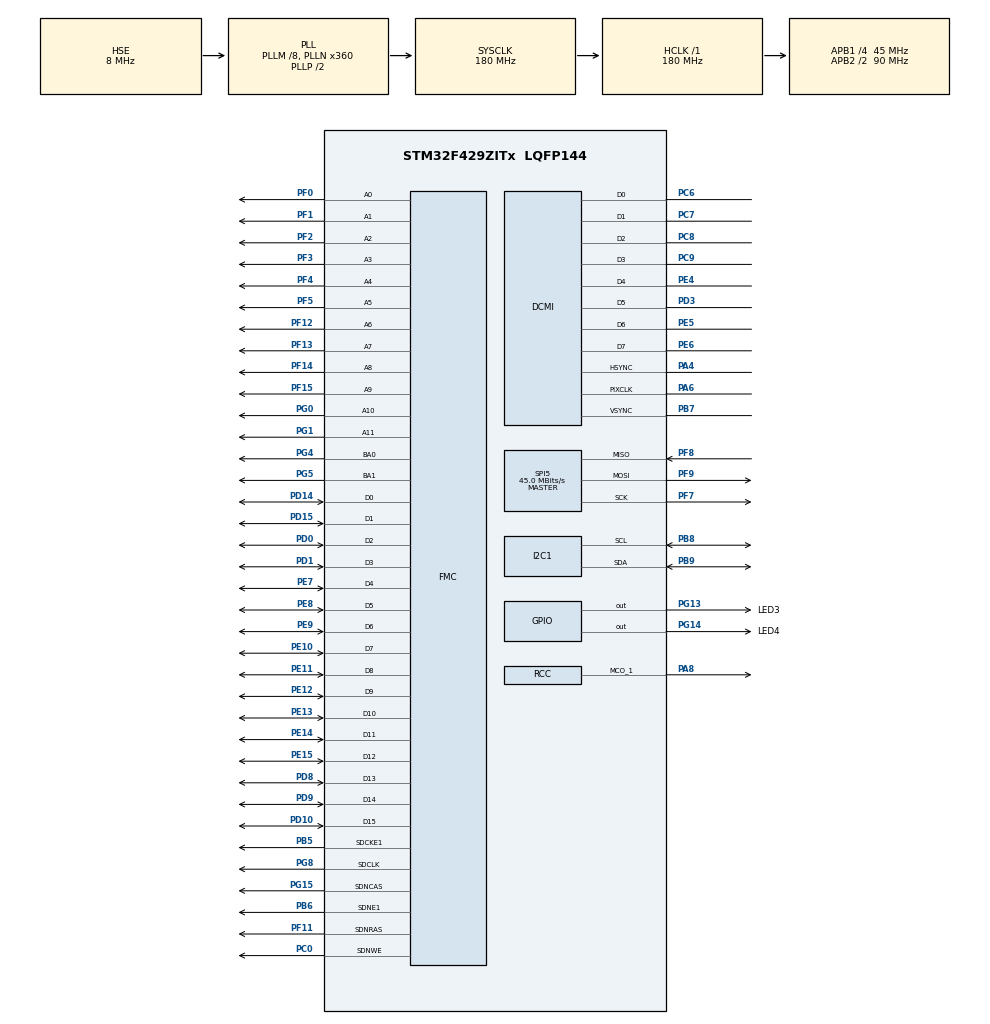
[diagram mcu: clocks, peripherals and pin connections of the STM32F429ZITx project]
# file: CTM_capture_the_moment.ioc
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DCMI.JPEGMode=DCMI_JPEG_DISABLE
Dma.DCMI.0.Direction=DMA_PERIPH_TO_MEMORY
Dma.DCMI.0.FIFOMode=DMA_FIFOMODE_DISABLE
Dma.DCMI.0.Instance=DMA2_Stream1
Dma.DCMI.0.MemDataAlignment=DMA_MDATAALIGN_WORD
Dma.DCMI.0.MemInc=DMA_MINC_ENABLE
Dma.DCMI.0.Mode=DMA_NORMAL
Dma.DCMI.0.PeriphDataAlignment=DMA_PDATAALIGN_WORD
Dma.DCMI.0.PeriphInc=DMA_PINC_DISABLE
Dma.DCMI.0.Priority=DMA_PRIORITY_HIGH
Dma.Request0=DCMI
FMC.CASLatency1=FMC_SDRAM_CAS_LATENCY_3
FMC.ExitSelfRefreshDelay1=7
FMC.LoadToActiveDelay1=2
FMC.RCDDelay1=2
FMC.RPDelay1=2
FMC.ReadBurst1=FMC_SDRAM_RBURST_DISABLE
FMC.ReadPipeDelay1=FMC_SDRAM_RPIPE_DELAY_1
FMC.RowCycleDelay1=7
FMC.SDClockPeriod1=FMC_SDRAM_CLOCK_PERIOD_3
FMC.SelfRefreshTime1=4
FMC.WriteRecoveryTime1=3
FREERTOS.BinarySemaphores01=sem_frame_captured,Dynamic,NULL,Available;sem_filter_done,Dynamic,NULL,Available
FREERTOS.Tasks01=CameraTask,24,128,StartCameraTask,Default,NULL,Dynamic,NULL,NULL;DisplayTask,8,128,StartDisplayTask,Default,NULL,Dynamic,NULL,NULL;FilterTask,8,128,StartFilterTask,Default,NULL,Dynamic,NULL,NULL
Mcu.Family=STM32F4
Mcu.Name=STM32F429ZITx
Mcu.Package=LQFP144
NVIC.DCMI_IRQn=true\:5\:0\:false\:false\:true\:true\:true\:true\:true
NVIC.DMA2_Stream1_IRQn=true\:5\:0\:false\:false\:true\:true\:false\:true\:true
NVIC.PriorityGroup=NVIC_PRIORITYGROUP_4
PA4.Mode=Slave_8_bits_External_Synchro
PA4.Signal=DCMI_HSYNC
PA6.Mode=Slave_8_bits_External_Synchro
PA6.Signal=DCMI_PIXCLK
PA8.GPIO_PuPd=GPIO_PULLUP
PA8.GPIO_Speed=GPIO_SPEED_FREQ_VERY_HIGH
PA8.Mode=Clock-out-1
PA8.Signal=RCC_MCO_1
PB5.Mode=SdramChipSelect2_1
PB5.Signal=FMC_SDCKE1
PB6.Mode=SdramChipSelect2_1
PB6.Signal=FMC_SDNE1
PB7.Mode=Slave_8_bits_External_Synchro
PB7.Signal=DCMI_VSYNC
PB8.GPIO_Pu=GPIO_PULLUP
PB8.Mode=I2C
PB8.Signal=I2C1_SCL
PB9.GPIO_Pu=GPIO_PULLUP
PB9.Mode=I2C
PB9.Signal=I2C1_SDA
PC0.Signal=FMC_SDNWE
PC6.Mode=Slave_8_bits_External_Synchro
PC6.Signal=DCMI_D0
PC7.Mode=Slave_8_bits_External_Synchro
PC7.Signal=DCMI_D1
PC8.Mode=Slave_8_bits_External_Synchro
PC8.Signal=DCMI_D2
PC9.Mode=Slave_8_bits_External_Synchro
PC9.Signal=DCMI_D3
PD0.Signal=FMC_D2_DA2
PD1.Signal=FMC_D3_DA3
PD10.Signal=FMC_D15_DA15
PD14.Signal=FMC_D0_DA0
PD15.Signal=FMC_D1_DA1
PD3.Mode=Slave_8_bits_External_Synchro
PD3.Signal=DCMI_D5
PD8.Signal=FMC_D13_DA13
PD9.Signal=FMC_D14_DA14
PE0.Signal=FMC_NBL0
PE1.Signal=FMC_NBL1
PE10.Signal=FMC_D7_DA7
PE11.Signal=FMC_D8_DA8
PE12.Signal=FMC_D9_DA9
PE13.Signal=FMC_D10_DA10
PE14.Signal=FMC_D11_DA11
PE15.Signal=FMC_D12_DA12
PE4.Mode=Slave_8_bits_External_Synchro
PE4.Signal=DCMI_D4
PE5.Mode=Slave_8_bits_External_Synchro
PE5.Signal=DCMI_D6
PE6.Mode=Slave_8_bits_External_Synchro
PE6.Signal=DCMI_D7
PE7.Signal=FMC_D4_DA4
PE8.Signal=FMC_D5_DA5
PE9.Signal=FMC_D6_DA6
PF0.Signal=FMC_A0
PF1.Signal=FMC_A1
PF11.Signal=FMC_SDNRAS
PF12.Signal=FMC_A6
PF13.Signal=FMC_A7
PF14.Signal=FMC_A8
PF15.Signal=FMC_A9
PF2.Signal=FMC_A2
PF3.Signal=FMC_A3
PF4.Signal=FMC_A4
PF5.Signal=FMC_A5
PF7.Mode=Full_Duplex_Master
PF7.Signal=SPI5_SCK
PF8.Mode=Full_Duplex_Master
PF8.Signal=SPI5_MISO
PF9.Mode=Full_Duplex_Master
PF9.Signal=SPI5_MOSI
PG0.Signal=FMC_A10
PG1.Signal=FMC_A11
PG13.GPIO_Label=LED3
PG13.Signal=GPIO_Output
PG14.GPIO_Label=LED4
PG14.Signal=GPIO_Output
PG15.Signal=FMC_SDNCAS
PG4.Signal=FMC_A14_BA0
PG5.Signal=FMC_A15_BA1
PG8.Signal=FMC_SDCLK
PH0/OSC_IN.Mode=HSE-External-Oscillator
PH0/OSC_IN.Signal=RCC_OSC_IN
PH1/OSC_OUT.Mode=HSE-External-Oscillator
PH1/OSC_OUT.Signal=RCC_OSC_OUT
ProjectManager.HeapSize=0x200
ProjectManager.StackSize=0x400
ProjectManager.TargetToolchain=STM32CubeIDE
RCC.48MHZClocksFreq_Value=51428571.428571425
RCC.AHBFreq_Value=180000000
RCC.APB1CLKDivider=RCC_HCLK_DIV4
RCC.APB1Freq_Value=45000000
RCC.APB1TimFreq_Value=90000000
RCC.APB2CLKDivider=RCC_HCLK_DIV2
RCC.APB2Freq_Value=90000000
RCC.APB2TimFreq_Value=180000000
RCC.CortexFreq_Value=180000000
RCC.HCLKFreq_Value=180000000
RCC.HSE_VALUE=8000000
RCC.HSI_VALUE=16000000
RCC.LSE_VALUE=32768
RCC.PLLM=8
RCC.PLLN=360
RCC.PLLQ=7
RCC.PLLSourceVirtual=RCC_PLLSOURCE_HSE
RCC.SYSCLKFreq_VALUE=180000000
RCC.SYSCLKSource=RCC_SYSCLKSOURCE_PLLCLK
RCC.VCOOutputFreq_Value=360000000
SH.FMC_A0.0=FMC_A0,12b-sda1
SH.FMC_A1.0=FMC_A1,12b-sda1
SH.FMC_A10.0=FMC_A10,12b-sda1
SH.FMC_A11.0=FMC_A11,12b-sda1
SH.FMC_A14_BA0.0=FMC_BA0,FourSdramBanks1
SH.FMC_A15_BA1.0=FMC_BA1,FourSdramBanks1
SH.FMC_A2.0=FMC_A2,12b-sda1
SH.FMC_A3.0=FMC_A3,12b-sda1
SH.FMC_A4.0=FMC_A4,12b-sda1
SH.FMC_A5.0=FMC_A5,12b-sda1
SH.FMC_A6.0=FMC_A6,12b-sda1
SH.FMC_A7.0=FMC_A7,12b-sda1
SH.FMC_A8.0=FMC_A8,12b-sda1
SH.FMC_A9.0=FMC_A9,12b-sda1
SH.FMC_D0_DA0.0=FMC_D0,sd-16b-d1
SH.FMC_D10_DA10.0=FMC_D10,sd-16b-d1
SH.FMC_D11_DA11.0=FMC_D11,sd-16b-d1
SH.FMC_D12_DA12.0=FMC_D12,sd-16b-d1
SH.FMC_D13_DA13.0=FMC_D13,sd-16b-d1
SH.FMC_D14_DA14.0=FMC_D14,sd-16b-d1
SH.FMC_D15_DA15.0=FMC_D15,sd-16b-d1
SH.FMC_D1_DA1.0=FMC_D1,sd-16b-d1
SH.FMC_D2_DA2.0=FMC_D2,sd-16b-d1
SH.FMC_D3_DA3.0=FMC_D3,sd-16b-d1
SH.FMC_D4_DA4.0=FMC_D4,sd-16b-d1
SH.FMC_D5_DA5.0=FMC_D5,sd-16b-d1
SH.FMC_D6_DA6.0=FMC_D6,sd-16b-d1
SH.FMC_D7_DA7.0=FMC_D7,sd-16b-d1
SH.FMC_D8_DA8.0=FMC_D8,sd-16b-d1
SH.FMC_D9_DA9.0=FMC_D9,sd-16b-d1
SH.FMC_NBL0.0=FMC_NBL0
SH.FMC_NBL1.0=FMC_NBL1
SH.FMC_SDCLK.0=FMC_SDCLK,12b-sda1
SH.FMC_SDNCAS.0=FMC_SDNCAS,12b-sda1
SH.FMC_SDNRAS.0=FMC_SDNRAS,12b-sda1
SH.FMC_SDNWE.0=FMC_SDNWE,12b-sda1
SPI5.CalculateBaudRate=45.0 MBits/s
SPI5.Direction=SPI_DIRECTION_2LINES
SPI5.Mode=SPI_MODE_MASTER
SPI5.VirtualType=VM_MASTER
VP_FREERTOS_VS_CMSIS_V2.Mode=CMSIS_V2
board=STM32F429I-DISC1

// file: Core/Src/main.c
/* USER CODE BEGIN Header */
/**
  ******************************************************************************
  * @file           : main.c
  * @brief          : Main program body
  ******************************************************************************
  * @attention
  *
  * Copyright (c) 2025 STMicroelectronics.
  * All rights reserved.
  *
  * This software is licensed under terms that can be found in the LICENSE file
  * in the root directory of this software component.
  * If no LICENSE file comes with this software, it is provided AS-IS.
  *
  ******************************************************************************
  */
/* USER CODE END Header */
#include "main.h"
#include "cmsis_os.h"

/* USER CODE BEGIN Includes */
#include "filter.h"
#include "lcd_drv.h"
#include "camera_drv.h"
/* USER CODE END Includes */

/* USER CODE BEGIN PD */
#define BUFFER_SIZE         ((uint32_t)0x0100)
#define WRITE_READ_ADDR     ((uint32_t)0x0800)
#define REFRESH_COUNT       ((uint32_t)0x056A)
static FilterType filterType = FILTER_NONE;

// Filtre değiştirme fonksiyonu
void cycleFilterType(void) {
    switch(filterType) {
        case FILTER_NONE:
            filterType = FILTER_GRAYSCALE;
            break;
        case FILTER_GRAYSCALE:
            filterType = FILTER_LAPLACIAN;
            break;
        case FILTER_LAPLACIAN:
            filterType = FILTER_GAUSSIAN;
            break;
        case FILTER_GAUSSIAN:
            filterType = FILTER_ROI;
            break;
        case FILTER_ROI:
        	filterType = FILTER_ROI_CENTER_ALARM;
        	break;
        case FILTER_ROI_CENTER_ALARM:
        	filterType = FILTER_NONE;
        	break;
        default:
            filterType = FILTER_NONE;
            break;
    }
}

// Test Defines
// Test görüntüsü boyutları
#define TEST_WIDTH 32
#define TEST_HEIGHT 32

// Test sonuçları için renkli çıktı
#define ANSI_COLOR_GREEN   "\x1b[32m"
#define ANSI_COLOR_RED     "\x1b[31m"
#define ANSI_COLOR_RESET   "\x1b[0m"

static void Fill_Buffer(uint32_t *pBuffer, uint32_t uwBufferLenght, uint32_t uwOffset);
/* USER CODE END PD */

DCMI_HandleTypeDef hdcmi;
DMA_HandleTypeDef hdma_dcmi;

I2C_HandleTypeDef hi2c1;

SPI_HandleTypeDef hspi5;

SDRAM_HandleTypeDef hsdram1;

/* Definitions for CameraTask */
osThreadId_t CameraTaskHandle;
const osThreadAttr_t CameraTask_attributes = {
  .name = "CameraTask",
  .stack_size = 128 * 4,
  .priority = (osPriority_t) osPriorityNormal,
};
/* Definitions for DisplayTask */
osThreadId_t DisplayTaskHandle;
const osThreadAttr_t DisplayTask_attributes = {
  .name = "DisplayTask",
  .stack_size = 128 * 4,
  .priority = (osPriority_t) osPriorityLow,
};
/* Definitions for FilterTask */
osThreadId_t FilterTaskHandle;
const osThreadAttr_t FilterTask_attributes = {
  .name = "FilterTask",
  .stack_size = 128 * 4,
  .priority = (osPriority_t) osPriorityLow,
};
/* Definitions for sem_frame_captured */
osSemaphoreId_t sem_frame_capturedHandle;
const osSemaphoreAttr_t sem_frame_captured_attributes = {
  .name = "sem_frame_captured"
};
/* Definitions for sem_filter_done */
osSemaphoreId_t sem_filter_doneHandle;
const osSemaphoreAttr_t sem_filter_done_attributes = {
  .name = "sem_filter_done"
};
/* USER CODE BEGIN PV */
FMC_SDRAM_CommandTypeDef command;
/* SDRAM Test  */
/* Read/Write Buffers */
uint32_t aTxBuffer[BUFFER_SIZE];
uint32_t aRxBuffer[BUFFER_SIZE];

/* Status variables */
__IO uint32_t uwWriteReadStatus = 0;

/* Counter index */
uint32_t uwIndex = 0;

/*Camera Variables */
uint16_t line_buffer[3][IMG_COLUMNS];             // 3 satırlık geçici buffer
uint16_t raw_image[IMG_ROWS * IMG_COLUMNS]; // Çıkış (her zaman RGB565)
__attribute__((section(".sdram"))) uint16_t filtered_image[IMG_ROWS * IMG_COLUMNS]; // Çıkış (her zaman RGB565)

// filter test
uint8_t grayscale_success, laplacian_success, roiopt_success, roialarm_success;

/* USER CODE END PV */

void SystemClock_Config(void);
static void MX_GPIO_Init(void);
static void MX_DMA_Init(void);
static void MX_SPI5_Init(void);
static void MX_DCMI_Init(void);
static void MX_I2C1_Init(void);
static void MX_FMC_Init(void);
void StartCameraTask(void *argument);
void StartDisplayTask(void *argument);
void StartFilterTask(void *argument);

/* USER CODE BEGIN PFP */
static void SDRAM_Initialization_Sequence(SDRAM_HandleTypeDef *hsdram, FMC_SDRAM_CommandTypeDef *Command);
/* USER CODE END PFP */

int main(void)
{

  /* MCU Configuration--------------------------------------------------------*/

  /* Reset of all peripherals, Initializes the Flash interface and the Systick. */
  HAL_Init();

  /* USER CODE BEGIN Init */
  te_CAMERA_ERROR_CODES cam_error;
  /* USER CODE END Init */

  /* Configure the system clock */
  SystemClock_Config();

  /* Initialize all configured peripherals */
  MX_GPIO_Init();
  MX_DMA_Init();
  MX_SPI5_Init();
  MX_DCMI_Init();
  MX_I2C1_Init();
  MX_FMC_Init();
  /* USER CODE BEGIN 2 */
  grayscale_success=0;
  laplacian_success=0;
  roiopt_success=0;
  roialarm_success=0;

  HAL_GPIO_WritePin(LED4_GPIO_Port, LED4_Pin, GPIO_PIN_SET);
  HAL_GPIO_WritePin(LED3_GPIO_Port, LED3_Pin, GPIO_PIN_SET);
  LCD_Open(NULL);
  cam_error = Camera_Open();

  if (cam_error != E_CAMERA_ERR_NONE) while(1);

  if (HAL_DCMI_Start_DMA(&hdcmi, DCMI_MODE_CONTINUOUS, (uint32_t)raw_image, IMG_ROWS*IMG_COLUMNS/2) != HAL_OK) {
    Error_Handler();
  }
  HAL_GPIO_WritePin(LED4_GPIO_Port, LED4_Pin, GPIO_PIN_RESET);
  HAL_GPIO_WritePin(LED3_GPIO_Port, LED3_Pin, GPIO_PIN_RESET);

  __HAL_DCMI_ENABLE_IT(&hdcmi, DCMI_IT_FRAME);

  /* Program the SDRAM external device */
    SDRAM_Initialization_Sequence(&hsdram1, &command);

    /* Fill the buffer to write */
      Fill_Buffer(aTxBuffer, BUFFER_SIZE, 0xA244250F);

      /* Write data to the SDRAM memory */
      for (uwIndex = 0; uwIndex < BUFFER_SIZE; uwIndex++)
      {
        *(__IO uint32_t*) (SDRAM_BANK_ADDR + WRITE_READ_ADDR + 4*uwIndex) = aTxBuffer[uwIndex];
      }

      /* Read back data from the SDRAM memory */
      for (uwIndex = 0; uwIndex < BUFFER_SIZE; uwIndex++)
      {
        aRxBuffer[uwIndex] = *(__IO uint32_t*) (SDRAM_BANK_ADDR + WRITE_READ_ADDR + 4*uwIndex);
       }

      /*##-3- Checking data integrity ############################################*/

        for (uwIndex = 0; (uwIndex < BUFFER_SIZE) && (uwWriteReadStatus == 0); uwIndex++)
        {
          if (aRxBuffer[uwIndex] != aTxBuffer[uwIndex])
          {
            uwWriteReadStatus++;
          }
        }

        if (uwWriteReadStatus)
        {
          /* KO */
          /* Turn on LED4 */
        	HAL_GPIO_WritePin(LED4_GPIO_Port, LED4_Pin, GPIO_PIN_SET);
        }
        else
        {
          /* OK */
          /* Turn on LED3 */
        	HAL_GPIO_WritePin(LED3_GPIO_Port, LED3_Pin, GPIO_PIN_SET);
        }

     // Filter Code Test
        //runFilterTests();
  /* USER CODE END 2 */

  /* Init scheduler */
  osKernelInitialize();

  /* Create the semaphores(s) */
  /* creation of sem_frame_captured */
  sem_frame_capturedHandle = osSemaphoreNew(1, 1, &sem_frame_captured_attributes);

  /* creation of sem_filter_done */
  sem_filter_doneHandle = osSemaphoreNew(1, 1, &sem_filter_done_attributes);

  /* Create the thread(s) */
  /* creation of CameraTask */
  CameraTaskHandle = osThreadNew(StartCameraTask, NULL, &CameraTask_attributes);

  /* creation of DisplayTask */
  DisplayTaskHandle = osThreadNew(StartDisplayTask, NULL, &DisplayTask_attributes);

  /* creation of FilterTask */
  FilterTaskHandle = osThreadNew(StartFilterTask, NULL, &FilterTask_attributes);

  /* Start scheduler */
  osKernelStart();

  /* We should never get here as control is now taken by the scheduler */

  /* Infinite loop */
  while (1)
  {

    /* USER CODE BEGIN 3 */
    // LCD_Display_Image((uint16_t *) processed_image);
  }
  /* USER CODE END 3 */
}

void SystemClock_Config(void)
{
  RCC_OscInitTypeDef RCC_OscInitStruct = {0};
  RCC_ClkInitTypeDef RCC_ClkInitStruct = {0};

  /** Configure the main internal regulator output voltage
  */
  __HAL_RCC_PWR_CLK_ENABLE();
  __HAL_PWR_VOLTAGESCALING_CONFIG(PWR_REGULATOR_VOLTAGE_SCALE1);

  /** Initializes the RCC Oscillators according to the specified parameters
  * in the RCC_OscInitTypeDef structure.
  */
  RCC_OscInitStruct.OscillatorType = RCC_OSCILLATORTYPE_HSI|RCC_OSCILLATORTYPE_HSE;
  RCC_OscInitStruct.HSEState = RCC_HSE_ON;
  RCC_OscInitStruct.HSIState = RCC_HSI_ON;
  RCC_OscInitStruct.HSICalibrationValue = RCC_HSICALIBRATION_DEFAULT;
  RCC_OscInitStruct.PLL.PLLState = RCC_PLL_ON;
  RCC_OscInitStruct.PLL.PLLSource = RCC_PLLSOURCE_HSE;
  RCC_OscInitStruct.PLL.PLLM = 8;
  RCC_OscInitStruct.PLL.PLLN = 360;
  RCC_OscInitStruct.PLL.PLLP = RCC_PLLP_DIV2;
  RCC_OscInitStruct.PLL.PLLQ = 7;
  if (HAL_RCC_OscConfig(&RCC_OscInitStruct) != HAL_OK)
  {
    Error_Handler();
  }

  /** Activate the Over-Drive mode
  */
  if (HAL_PWREx_EnableOverDrive() != HAL_OK)
  {
    Error_Handler();
  }

  /** Initializes the CPU, AHB and APB buses clocks
  */
  RCC_ClkInitStruct.ClockType = RCC_CLOCKTYPE_HCLK|RCC_CLOCKTYPE_SYSCLK
                              |RCC_CLOCKTYPE_PCLK1|RCC_CLOCKTYPE_PCLK2;
  RCC_ClkInitStruct.SYSCLKSource = RCC_SYSCLKSOURCE_PLLCLK;
  RCC_ClkInitStruct.AHBCLKDivider = RCC_SYSCLK_DIV1;
  RCC_ClkInitStruct.APB1CLKDivider = RCC_HCLK_DIV4;
  RCC_ClkInitStruct.APB2CLKDivider = RCC_HCLK_DIV2;

  if (HAL_RCC_ClockConfig(&RCC_ClkInitStruct, FLASH_LATENCY_5) != HAL_OK)
  {
    Error_Handler();
  }
  HAL_RCC_MCOConfig(RCC_MCO1, RCC_MCO1SOURCE_HSI, RCC_MCODIV_1);
}

static void MX_DCMI_Init(void)
{

  hdcmi.Instance = DCMI;
  hdcmi.Init.SynchroMode = DCMI_SYNCHRO_HARDWARE;
  hdcmi.Init.PCKPolarity = DCMI_PCKPOLARITY_FALLING;
  hdcmi.Init.VSPolarity = DCMI_VSPOLARITY_LOW;
  hdcmi.Init.HSPolarity = DCMI_HSPOLARITY_LOW;
  hdcmi.Init.CaptureRate = DCMI_CR_ALL_FRAME;
  hdcmi.Init.ExtendedDataMode = DCMI_EXTEND_DATA_8B;
  hdcmi.Init.JPEGMode = DCMI_JPEG_DISABLE;
  if (HAL_DCMI_Init(&hdcmi) != HAL_OK)
  {
    Error_Handler();
  }

}

static void MX_I2C1_Init(void)
{

  hi2c1.Instance = I2C1;
  hi2c1.Init.ClockSpeed = 100000;
  hi2c1.Init.DutyCycle = I2C_DUTYCYCLE_2;
  hi2c1.Init.OwnAddress1 = 0;
  hi2c1.Init.AddressingMode = I2C_ADDRESSINGMODE_7BIT;
  hi2c1.Init.DualAddressMode = I2C_DUALADDRESS_DISABLE;
  hi2c1.Init.OwnAddress2 = 0;
  hi2c1.Init.GeneralCallMode = I2C_GENERALCALL_DISABLE;
  hi2c1.Init.NoStretchMode = I2C_NOSTRETCH_DISABLE;
  if (HAL_I2C_Init(&hi2c1) != HAL_OK)
  {
    Error_Handler();
  }

  /** Configure Analogue filter
  */
  if (HAL_I2CEx_ConfigAnalogFilter(&hi2c1, I2C_ANALOGFILTER_ENABLE) != HAL_OK)
  {
    Error_Handler();
  }

  /** Configure Digital filter
  */
  if (HAL_I2CEx_ConfigDigitalFilter(&hi2c1, 0) != HAL_OK)
  {
    Error_Handler();
  }

}

static void MX_SPI5_Init(void)
{

  /* SPI5 parameter configuration*/
  hspi5.Instance = SPI5;
  hspi5.Init.Mode = SPI_MODE_MASTER;
  hspi5.Init.Direction = SPI_DIRECTION_2LINES;
  hspi5.Init.DataSize = SPI_DATASIZE_8BIT;
  hspi5.Init.CLKPolarity = SPI_POLARITY_LOW;
  hspi5.Init.CLKPhase = SPI_PHASE_1EDGE;
  hspi5.Init.NSS = SPI_NSS_SOFT;
  hspi5.Init.BaudRatePrescaler = SPI_BAUDRATEPRESCALER_2;
  hspi5.Init.FirstBit = SPI_FIRSTBIT_MSB;
  hspi5.Init.TIMode = SPI_TIMODE_DISABLE;
  hspi5.Init.CRCCalculation = SPI_CRCCALCULATION_DISABLE;
  hspi5.Init.CRCPolynomial = 10;
  if (HAL_SPI_Init(&hspi5) != HAL_OK)
  {
    Error_Handler();
  }

}

static void MX_DMA_Init(void)
{

  /* DMA controller clock enable */
  __HAL_RCC_DMA2_CLK_ENABLE();

  /* DMA interrupt init */
  /* DMA2_Stream1_IRQn interrupt configuration */
  HAL_NVIC_SetPriority(DMA2_Stream1_IRQn, 5, 0);
  HAL_NVIC_EnableIRQ(DMA2_Stream1_IRQn);

}

/* FMC initialization function */
static void MX_FMC_Init(void)
{

  FMC_SDRAM_TimingTypeDef SdramTiming = {0};

  /** Perform the SDRAM1 memory initialization sequence
  */
  hsdram1.Instance = FMC_SDRAM_DEVICE;
  /* hsdram1.Init */
  hsdram1.Init.SDBank = FMC_SDRAM_BANK2;
  hsdram1.Init.ColumnBitsNumber = FMC_SDRAM_COLUMN_BITS_NUM_8;
  hsdram1.Init.RowBitsNumber = FMC_SDRAM_ROW_BITS_NUM_12;
  hsdram1.Init.MemoryDataWidth = FMC_SDRAM_MEM_BUS_WIDTH_16;
  hsdram1.Init.InternalBankNumber = FMC_SDRAM_INTERN_BANKS_NUM_4;
  hsdram1.Init.CASLatency = FMC_SDRAM_CAS_LATENCY_3;
  hsdram1.Init.WriteProtection = FMC_SDRAM_WRITE_PROTECTION_DISABLE;
  hsdram1.Init.SDClockPeriod = FMC_SDRAM_CLOCK_PERIOD_3;
  hsdram1.Init.ReadBurst = FMC_SDRAM_RBURST_DISABLE;
  hsdram1.Init.ReadPipeDelay = FMC_SDRAM_RPIPE_DELAY_1;
  /* SdramTiming */
  SdramTiming.LoadToActiveDelay = 2;
  SdramTiming.ExitSelfRefreshDelay = 7;
  SdramTiming.SelfRefreshTime = 4;
  SdramTiming.RowCycleDelay = 7;
  SdramTiming.WriteRecoveryTime = 3;
  SdramTiming.RPDelay = 2;
  SdramTiming.RCDDelay = 2;

  if (HAL_SDRAM_Init(&hsdram1, &SdramTiming) != HAL_OK)
  {
    Error_Handler( );
  }

  /* USER CODE BEGIN FMC_Init 2 */
  static GPIO_TypeDef * const GPIOInitTable[] = {
    GPIOF, GPIOF, GPIOF, GPIOF, GPIOF, GPIOF, GPIOF, GPIOF, GPIOF, GPIOF, GPIOG, GPIOG,
    GPIOD, GPIOD, GPIOD, GPIOD, GPIOE, GPIOE, GPIOE, GPIOE, GPIOE, GPIOE, GPIOE, GPIOE, GPIOE, GPIOD,   GPIOD, GPIOD,
    GPIOB, GPIOB, GPIOC, GPIOE, GPIOE, GPIOF, GPIOG, GPIOG, GPIOG, GPIOG,
    0};

  static uint8_t const PINInitTable[] = {
    0, 1, 2, 3, 4, 5, 12, 13, 14, 15, 0, 1,
    14, 15, 0, 1, 7, 8, 9, 10, 11, 12, 13, 14, 15, 8,
    9, 10,
    5, 6, 0, 0, 1, 11, 4, 5, 8, 15,
    0};

  /* USER CODE END FMC_Init 2 */
}

static void MX_GPIO_Init(void)
{
  GPIO_InitTypeDef GPIO_InitStruct = {0};

  /* GPIO Ports Clock Enable */
  __HAL_RCC_GPIOE_CLK_ENABLE();
  __HAL_RCC_GPIOF_CLK_ENABLE();
  __HAL_RCC_GPIOH_CLK_ENABLE();
  __HAL_RCC_GPIOC_CLK_ENABLE();
  __HAL_RCC_GPIOA_CLK_ENABLE();
  __HAL_RCC_GPIOG_CLK_ENABLE();
  __HAL_RCC_GPIOD_CLK_ENABLE();
  __HAL_RCC_GPIOB_CLK_ENABLE();

  /*Configure GPIO pin Output Level */
  HAL_GPIO_WritePin(GPIOG, LED3_Pin|LED4_Pin, GPIO_PIN_RESET);

  // Filtre değiştirme butonu için GPIO ayarı
  GPIO_InitStruct.Pin = GPIO_PIN_0;
  GPIO_InitStruct.Mode = GPIO_MODE_IT_RISING;
  GPIO_InitStruct.Pull = GPIO_PULLDOWN;
  HAL_GPIO_Init(GPIOA, &GPIO_InitStruct);

  // Buton interrupt'ını aktifleştir
  HAL_NVIC_SetPriority(EXTI0_IRQn, 5, 0);
  HAL_NVIC_EnableIRQ(EXTI0_IRQn);

  /*Configure GPIO pin : PA8 */
  GPIO_InitStruct.Pin = GPIO_PIN_8;
  GPIO_InitStruct.Mode = GPIO_MODE_AF_PP;
  GPIO_InitStruct.Pull = GPIO_PULLUP;
  GPIO_InitStruct.Speed = GPIO_SPEED_FREQ_VERY_HIGH;
  GPIO_InitStruct.Alternate = GPIO_AF0_MCO;
  HAL_GPIO_Init(GPIOA, &GPIO_InitStruct);

  /*Configure GPIO pins : LED3_Pin LED4_Pin */
  GPIO_InitStruct.Pin = LED3_Pin|LED4_Pin;
  GPIO_InitStruct.Mode = GPIO_MODE_OUTPUT_PP;
  GPIO_InitStruct.Pull = GPIO_NOPULL;
  GPIO_InitStruct.Speed = GPIO_SPEED_FREQ_LOW;
  HAL_GPIO_Init(GPIOG, &GPIO_InitStruct);

  /* USER CODE BEGIN MX_GPIO_Init_2 */
  // FMC_D0 - PD14
  __HAL_RCC_GPIOD_CLK_ENABLE();
  GPIO_InitStruct.Pin = GPIO_PIN_14;
  GPIO_InitStruct.Mode = GPIO_MODE_AF_PP;
  GPIO_InitStruct.Pull = GPIO_NOPULL;
  GPIO_InitStruct.Speed = GPIO_SPEED_FREQ_VERY_HIGH;
  GPIO_InitStruct.Alternate = GPIO_AF12_FMC;
  HAL_GPIO_Init(GPIOD, &GPIO_InitStruct);

  // FMC_D1 - PD15
  __HAL_RCC_GPIOD_CLK_ENABLE();
  GPIO_InitStruct.Pin = GPIO_PIN_15;
  GPIO_InitStruct.Mode = GPIO_MODE_AF_PP;
  GPIO_InitStruct.Pull = GPIO_NOPULL;
  GPIO_InitStruct.Speed = GPIO_SPEED_FREQ_VERY_HIGH;
  GPIO_InitStruct.Alternate = GPIO_AF12_FMC;
  HAL_GPIO_Init(GPIOD, &GPIO_InitStruct);

  // FMC_D2 - PD0
  __HAL_RCC_GPIOD_CLK_ENABLE();
  GPIO_InitStruct.Pin = GPIO_PIN_0;
  GPIO_InitStruct.Mode = GPIO_MODE_AF_PP;
  GPIO_InitStruct.Pull = GPIO_NOPULL;
  GPIO_InitStruct.Speed = GPIO_SPEED_FREQ_VERY_HIGH;
  GPIO_InitStruct.Alternate = GPIO_AF12_FMC;
  HAL_GPIO_Init(GPIOD, &GPIO_InitStruct);

  // FMC_D3 - PD1
  __HAL_RCC_GPIOD_CLK_ENABLE();
  GPIO_InitStruct.Pin = GPIO_PIN_1;
  GPIO_InitStruct.Mode = GPIO_MODE_AF_PP;
  GPIO_InitStruct.Pull = GPIO_NOPULL;
  GPIO_InitStruct.Speed = GPIO_SPEED_FREQ_VERY_HIGH;
  GPIO_InitStruct.Alternate = GPIO_AF12_FMC;
  HAL_GPIO_Init(GPIOD, &GPIO_InitStruct);

  // FMC_D4 - PE7
  __HAL_RCC_GPIOE_CLK_ENABLE();
  GPIO_InitStruct.Pin = GPIO_PIN_7;
  GPIO_InitStruct.Mode = GPIO_MODE_AF_PP;
  GPIO_InitStruct.Pull = GPIO_NOPULL;
  GPIO_InitStruct.Speed = GPIO_SPEED_FREQ_VERY_HIGH;
  GPIO_InitStruct.Alternate = GPIO_AF12_FMC;
  HAL_GPIO_Init(GPIOE, &GPIO_InitStruct);

  // FMC_D5 - PE8
  __HAL_RCC_GPIOE_CLK_ENABLE();
  GPIO_InitStruct.Pin = GPIO_PIN_8;
  GPIO_InitStruct.Mode = GPIO_MODE_AF_PP;
  GPIO_InitStruct.Pull = GPIO_NOPULL;
  GPIO_InitStruct.Speed = GPIO_SPEED_FREQ_VERY_HIGH;
  GPIO_InitStruct.Alternate = GPIO_AF12_FMC;
  HAL_GPIO_Init(GPIOE, &GPIO_InitStruct);

  // FMC_D6 - PE9
  __HAL_RCC_GPIOE_CLK_ENABLE();
  GPIO_InitStruct.Pin = GPIO_PIN_9;
  GPIO_InitStruct.Mode = GPIO_MODE_AF_PP;
  GPIO_InitStruct.Pull = GPIO_NOPULL;
  GPIO_InitStruct.Speed = GPIO_SPEED_FREQ_VERY_HIGH;
  GPIO_InitStruct.Alternate = GPIO_AF12_FMC;
  HAL_GPIO_Init(GPIOE, &GPIO_InitStruct);

  // FMC_D7 - PE10
  __HAL_RCC_GPIOE_CLK_ENABLE();
  GPIO_InitStruct.Pin = GPIO_PIN_10;
  GPIO_InitStruct.Mode = GPIO_MODE_AF_PP;
  GPIO_InitStruct.Pull = GPIO_NOPULL;
  GPIO_InitStruct.Speed = GPIO_SPEED_FREQ_VERY_HIGH;
  GPIO_InitStruct.Alternate = GPIO_AF12_FMC;
  HAL_GPIO_Init(GPIOE, &GPIO_InitStruct);

  // FMC_D8 - PE11
  __HAL_RCC_GPIOE_CLK_ENABLE();
  GPIO_InitStruct.Pin = GPIO_PIN_11;
  GPIO_InitStruct.Mode = GPIO_MODE_AF_PP;
  GPIO_InitStruct.Pull = GPIO_NOPULL;
  GPIO_InitStruct.Speed = GPIO_SPEED_FREQ_VERY_HIGH;
  GPIO_InitStruct.Alternate = GPIO_AF12_FMC;
  HAL_GPIO_Init(GPIOE, &GPIO_InitStruct);

  // FMC_D9 - PE12
  __HAL_RCC_GPIOE_CLK_ENABLE();
  GPIO_InitStruct.Pin = GPIO_PIN_12;
  GPIO_InitStruct.Mode = GPIO_MODE_AF_PP;
  GPIO_InitStruct.Pull = GPIO_NOPULL;
  GPIO_InitStruct.Speed = GPIO_SPEED_FREQ_VERY_HIGH;
  GPIO_InitStruct.Alternate = GPIO_AF12_FMC;
  HAL_GPIO_Init(GPIOE, &GPIO_InitStruct);

  // FMC_D10 - PE13
  __HAL_RCC_GPIOE_CLK_ENABLE();
  GPIO_InitStruct.Pin = GPIO_PIN_13;
  GPIO_InitStruct.Mode = GPIO_MODE_AF_PP;
  GPIO_InitStruct.Pull = GPIO_NOPULL;
  GPIO_InitStruct.Speed = GPIO_SPEED_FREQ_VERY_HIGH;
  GPIO_InitStruct.Alternate = GPIO_AF12_FMC;
  HAL_GPIO_Init(GPIOE, &GPIO_InitStruct);

  // FMC_D11 - PE14
  __HAL_RCC_GPIOE_CLK_ENABLE();
  GPIO_InitStruct.Pin = GPIO_PIN_14;
  GPIO_InitStruct.Mode = GPIO_MODE_AF_PP;
  GPIO_InitStruct.Pull = GPIO_NOPULL;
  GPIO_InitStruct.Speed = GPIO_SPEED_FREQ_VERY_HIGH;
  GPIO_InitStruct.Alternate = GPIO_AF12_FMC;
  HAL_GPIO_Init(GPIOE, &GPIO_InitStruct);

  // FMC_D12 - PE15
  __HAL_RCC_GPIOE_CLK_ENABLE();
  GPIO_InitStruct.Pin = GPIO_PIN_15;
  GPIO_InitStruct.Mode = GPIO_MODE_AF_PP;
  GPIO_InitStruct.Pull = GPIO_NOPULL;
  GPIO_InitStruct.Speed = GPIO_SPEED_FREQ_VERY_HIGH;
  GPIO_InitStruct.Alternate = GPIO_AF12_FMC;
  HAL_GPIO_Init(GPIOE, &GPIO_InitStruct);

  // FMC_D13 - PD8
  __HAL_RCC_GPIOD_CLK_ENABLE();
  GPIO_InitStruct.Pin = GPIO_PIN_8;
  GPIO_InitStruct.Mode = GPIO_MODE_AF_PP;
  GPIO_InitStruct.Pull = GPIO_NOPULL;
  GPIO_InitStruct.Speed = GPIO_SPEED_FREQ_VERY_HIGH;
  GPIO_InitStruct.Alternate = GPIO_AF12_FMC;
  HAL_GPIO_Init(GPIOD, &GPIO_InitStruct);

  // FMC_D14 - PD9
  __HAL_RCC_GPIOD_CLK_ENABLE();
  GPIO_InitStruct.Pin = GPIO_PIN_9;
  GPIO_InitStruct.Mode = GPIO_MODE_AF_PP;
  GPIO_InitStruct.Pull = GPIO_NOPULL;
  GPIO_InitStruct.Speed = GPIO_SPEED_FREQ_VERY_HIGH;
  GPIO_InitStruct.Alternate = GPIO_AF12_FMC;
  HAL_GPIO_Init(GPIOD, &GPIO_InitStruct);

  // FMC_D15 - PD10
  __HAL_RCC_GPIOD_CLK_ENABLE();
  GPIO_InitStruct.Pin = GPIO_PIN_10;
  GPIO_InitStruct.Mode = GPIO_MODE_AF_PP;
  GPIO_InitStruct.Pull = GPIO_NOPULL;
  GPIO_InitStruct.Speed = GPIO_SPEED_FREQ_VERY_HIGH;
  GPIO_InitStruct.Alternate = GPIO_AF12_FMC;
  HAL_GPIO_Init(GPIOD, &GPIO_InitStruct);

  // FMC_A0 - PF0
  __HAL_RCC_GPIOF_CLK_ENABLE();
  GPIO_InitStruct.Pin = GPIO_PIN_0;
  GPIO_InitStruct.Mode = GPIO_MODE_AF_PP;
  GPIO_InitStruct.Pull = GPIO_NOPULL;
  GPIO_InitStruct.Speed = GPIO_SPEED_FREQ_VERY_HIGH;
  GPIO_InitStruct.Alternate = GPIO_AF12_FMC;
  HAL_GPIO_Init(GPIOF, &GPIO_InitStruct);

  // FMC_A1 - PF1
  __HAL_RCC_GPIOF_CLK_ENABLE();
  GPIO_InitStruct.Pin = GPIO_PIN_1;
  GPIO_InitStruct.Mode = GPIO_MODE_AF_PP;
  GPIO_InitStruct.Pull = GPIO_NOPULL;
  GPIO_InitStruct.Speed = GPIO_SPEED_FREQ_VERY_HIGH;
  GPIO_InitStruct.Alternate = GPIO_AF12_FMC;
  HAL_GPIO_Init(GPIOF, &GPIO_InitStruct);

  // FMC_A2 - PF2
  __HAL_RCC_GPIOF_CLK_ENABLE();
  GPIO_InitStruct.Pin = GPIO_PIN_2;
  GPIO_InitStruct.Mode = GPIO_MODE_AF_PP;
  GPIO_InitStruct.Pull = GPIO_NOPULL;
  GPIO_InitStruct.Speed = GPIO_SPEED_FREQ_VERY_HIGH;
  GPIO_InitStruct.Alternate = GPIO_AF12_FMC;
  HAL_GPIO_Init(GPIOF, &GPIO_InitStruct);

  // FMC_A3 - PF3
  __HAL_RCC_GPIOF_CLK_ENABLE();
  GPIO_InitStruct.Pin = GPIO_PIN_3;
  GPIO_InitStruct.Mode = GPIO_MODE_AF_PP;
  GPIO_InitStruct.Pull = GPIO_NOPULL;
  GPIO_InitStruct.Speed = GPIO_SPEED_FREQ_VERY_HIGH;
  GPIO_InitStruct.Alternate = GPIO_AF12_FMC;
  HAL_GPIO_Init(GPIOF, &GPIO_InitStruct);

  // FMC_A4 - PF4
  __HAL_RCC_GPIOF_CLK_ENABLE();
  GPIO_InitStruct.Pin = GPIO_PIN_4;
  GPIO_InitStruct.Mode = GPIO_MODE_AF_PP;
  GPIO_InitStruct.Pull = GPIO_NOPULL;
  GPIO_InitStruct.Speed = GPIO_SPEED_FREQ_VERY_HIGH;
  GPIO_InitStruct.Alternate = GPIO_AF12_FMC;
  HAL_GPIO_Init(GPIOF, &GPIO_InitStruct);

  // FMC_A5 - PF5
  __HAL_RCC_GPIOF_CLK_ENABLE();
  GPIO_InitStruct.Pin = GPIO_PIN_5;
  GPIO_InitStruct.Mode = GPIO_MODE_AF_PP;
  GPIO_InitStruct.Pull = GPIO_NOPULL;
  GPIO_InitStruct.Speed = GPIO_SPEED_FREQ_VERY_HIGH;
  GPIO_InitStruct.Alternate = GPIO_AF12_FMC;
  HAL_GPIO_Init(GPIOF, &GPIO_InitStruct);

  // FMC_A10 - PG0
  __HAL_RCC_GPIOG_CLK_ENABLE();
  GPIO_InitStruct.Pin = GPIO_PIN_0;
  GPIO_InitStruct.Mode = GPIO_MODE_AF_PP;
  GPIO_InitStruct.Pull = GPIO_NOPULL;
  GPIO_InitStruct.Speed = GPIO_SPEED_FREQ_VERY_HIGH;
  GPIO_InitStruct.Alternate = GPIO_AF12_FMC;
  HAL_GPIO_Init(GPIOG, &GPIO_InitStruct);

  // FMC_A11 - PG1
  __HAL_RCC_GPIOG_CLK_ENABLE();
  GPIO_InitStruct.Pin = GPIO_PIN_1;
  GPIO_InitStruct.Mode = GPIO_MODE_AF_PP;
  GPIO_InitStruct.Pull = GPIO_NOPULL;
  GPIO_InitStruct.Speed = GPIO_SPEED_FREQ_VERY_HIGH;
  GPIO_InitStruct.Alternate = GPIO_AF12_FMC;
  HAL_GPIO_Init(GPIOG, &GPIO_InitStruct);

  // FMC_SDNE1 - PC2
  __HAL_RCC_GPIOC_CLK_ENABLE();
  GPIO_InitStruct.Pin = GPIO_PIN_2;
  GPIO_InitStruct.Mode = GPIO_MODE_AF_PP;
  GPIO_InitStruct.Pull = GPIO_NOPULL;
  GPIO_InitStruct.Speed = GPIO_SPEED_FREQ_VERY_HIGH;
  GPIO_InitStruct.Alternate = GPIO_AF12_FMC;
  HAL_GPIO_Init(GPIOC, &GPIO_InitStruct);

  // FMC_SDCKE1 - PC3
  __HAL_RCC_GPIOC_CLK_ENABLE();
  GPIO_InitStruct.Pin = GPIO_PIN_3;
  GPIO_InitStruct.Mode = GPIO_MODE_AF_PP;
  GPIO_InitStruct.Pull = GPIO_NOPULL;
  GPIO_InitStruct.Speed = GPIO_SPEED_FREQ_VERY_HIGH;
  GPIO_InitStruct.Alternate = GPIO_AF12_FMC;
  HAL_GPIO_Init(GPIOC, &GPIO_InitStruct);

  // FMC_SDCLK - PG8
  __HAL_RCC_GPIOG_CLK_ENABLE();
  GPIO_InitStruct.Pin = GPIO_PIN_8;
  GPIO_InitStruct.Mode = GPIO_MODE_AF_PP;
  GPIO_InitStruct.Pull = GPIO_NOPULL;
  GPIO_InitStruct.Speed = GPIO_SPEED_FREQ_VERY_HIGH;
  GPIO_InitStruct.Alternate = GPIO_AF12_FMC;
  HAL_GPIO_Init(GPIOG, &GPIO_InitStruct);

  // FMC_SDNCAS - PG15
  __HAL_RCC_GPIOG_CLK_ENABLE();
  GPIO_InitStruct.Pin = GPIO_PIN_15;
  GPIO_InitStruct.Mode = GPIO_MODE_AF_PP;
  GPIO_InitStruct.Pull = GPIO_NOPULL;
  GPIO_InitStruct.Speed = GPIO_SPEED_FREQ_VERY_HIGH;
  GPIO_InitStruct.Alternate = GPIO_AF12_FMC;
  HAL_GPIO_Init(GPIOG, &GPIO_InitStruct);

  // FMC_SDNRAS - PF11
  __HAL_RCC_GPIOF_CLK_ENABLE();
  GPIO_InitStruct.Pin = GPIO_PIN_11;
  GPIO_InitStruct.Mode = GPIO_MODE_AF_PP;
  GPIO_InitStruct.Pull = GPIO_NOPULL;
  GPIO_InitStruct.Speed = GPIO_SPEED_FREQ_VERY_HIGH;
  GPIO_InitStruct.Alternate = GPIO_AF12_FMC;
  HAL_GPIO_Init(GPIOF, &GPIO_InitStruct);

  // FMC_SDNWE - PD5
  __HAL_RCC_GPIOD_CLK_ENABLE();
  GPIO_InitStruct.Pin = GPIO_PIN_5;
  GPIO_InitStruct.Mode = GPIO_MODE_AF_PP;
  GPIO_InitStruct.Pull = GPIO_NOPULL;
  GPIO_InitStruct.Speed = GPIO_SPEED_FREQ_VERY_HIGH;
  GPIO_InitStruct.Alternate = GPIO_AF12_FMC;
  HAL_GPIO_Init(GPIOD, &GPIO_InitStruct);
  /* USER CODE END MX_GPIO_Init_2 */
}

/* USER CODE BEGIN 4 */
//void HAL_DCMI_FrameEventCallback(DCMI_HandleTypeDef *hdcmi)
//{
//	applyFilterToImageFull(raw_image, filtered_image, filterType);
//	LCD_Display_Image((uint16_t *) filtered_image);
//}
void HAL_DCMI_FrameEventCallback(DCMI_HandleTypeDef *hdcmi)
{
  osSemaphoreRelease(sem_frame_capturedHandle);
}

static void SDRAM_Initialization_Sequence(SDRAM_HandleTypeDef *hsdram, FMC_SDRAM_CommandTypeDef *Command)
{
  __IO uint32_t tmpmrd =0;
  /* Step 3:  Configure a clock configuration enable command */
  Command->CommandMode 			 = FMC_SDRAM_CMD_CLK_ENABLE;
  Command->CommandTarget 		 = FMC_SDRAM_CMD_TARGET_BANK2;
  Command->AutoRefreshNumber 	 = 1;
  Command->ModeRegisterDefinition = 0;

  /* Send the command */
  HAL_SDRAM_SendCommand(hsdram, Command, 0x1000);

  /* Step 4: Insert 100 ms delay */
  HAL_Delay(100);

  /* Step 5: Configure a PALL (precharge all) command */
  Command->CommandMode 			 = FMC_SDRAM_CMD_PALL;
  Command->CommandTarget 	     = FMC_SDRAM_CMD_TARGET_BANK2;
  Command->AutoRefreshNumber 	 = 1;
  Command->ModeRegisterDefinition = 0;

  /* Send the command */
  HAL_SDRAM_SendCommand(hsdram, Command, 0x1000);

  /* Step 6 : Configure a Auto-Refresh command */
  Command->CommandMode 			 = FMC_SDRAM_CMD_AUTOREFRESH_MODE;
  Command->CommandTarget 		 = FMC_SDRAM_CMD_TARGET_BANK2;
  Command->AutoRefreshNumber 	 = 4;
  Command->ModeRegisterDefinition = 0;

  /* Send the command */
  HAL_SDRAM_SendCommand(hsdram, Command, 0x1000);

  /* Step 7: Program the external memory mode register */
  tmpmrd = (uint32_t)SDRAM_MODEREG_BURST_LENGTH_2          |
                     SDRAM_MODEREG_BURST_TYPE_SEQUENTIAL   |
                     SDRAM_MODEREG_CAS_LATENCY_3           |
                     SDRAM_MODEREG_OPERATING_MODE_STANDARD |
                     SDRAM_MODEREG_WRITEBURST_MODE_SINGLE;

  Command->CommandMode = FMC_SDRAM_CMD_LOAD_MODE;
  Command->CommandTarget 		 = FMC_SDRAM_CMD_TARGET_BANK2;
  Command->AutoRefreshNumber 	 = 1;
  Command->ModeRegisterDefinition = tmpmrd;

  /* Send the command */
  HAL_SDRAM_SendCommand(hsdram, Command, 0x1000);

  /* Step 8: Set the refresh rate counter */
  /* (15.62 us x Freq) - 20 */
  /* Set the device refresh counter */
  HAL_SDRAM_ProgramRefreshRate(hsdram, REFRESH_COUNT);
}

static void Fill_Buffer(uint32_t *pBuffer, uint32_t uwBufferLenght, uint32_t uwOffset)
{
  uint32_t tmpIndex = 0;

  /* Put in global buffer different values */
  for (tmpIndex = 0; tmpIndex < uwBufferLenght; tmpIndex++ )
  {
    pBuffer[tmpIndex] = tmpIndex + uwOffset;
  }
}

// Ana test fonksiyonu
void runFilterTests(void) {
    testGrayscaleFilter();

    testLaplacianFilter();

    testROIOptimization();

    testCenterROIAlarm();
}

// Test görüntüsü oluşturma
static void createTestImage(uint16_t *image, int pattern) {
    for (int y = 0; y < TEST_HEIGHT; y++) {
        for (int x = 0; x < TEST_WIDTH; x++) {
            switch (pattern) {
                case 0: // Düz gri
                    image[y * TEST_WIDTH + x] = 0x8410; // RGB565 format
                    break;
                case 1: // Dikey çizgiler
                    image[y * TEST_WIDTH + x] = (x % 2) ? 0xFFFF : 0x0000;
                    break;
                case 2: // Yatay çizgiler
                    image[y * TEST_WIDTH + x] = (y % 2) ? 0xFFFF : 0x0000;
                    break;
                case 3: // Dama tahtası
                    image[y * TEST_WIDTH + x] = ((x + y) % 2) ? 0xFFFF : 0x0000;
                    break;
            }
        }
    }
}

// Test sonucu kontrolü
static int compareImages(uint16_t *img1, uint16_t *img2, int size) {
    int diff = 0;
    for (int i = 0; i < size; i++) {
        if (img1[i] != img2[i]) diff++;
    }
    return diff;
}

// Grayscale filtre testi
static void testGrayscaleFilter(void) {
    uint16_t input[TEST_WIDTH * TEST_HEIGHT];
    uint16_t output[TEST_WIDTH * TEST_HEIGHT];
    uint16_t expected[TEST_WIDTH * TEST_HEIGHT];

    // printf("Test: Grayscale Filtresi\n");

    // Test 1: Düz gri görüntü
    createTestImage(input, 0);
    memset(output, 0, sizeof(output));
    applyFilterToImageFull(input, output, FILTER_GRAYSCALE);

    // Düz gri görüntü için çıktı aynı olmalı
    int diff = compareImages(input, output, TEST_WIDTH * TEST_HEIGHT);
    // printf("  Test 1 (Düz Gri): %s%s%s\n",
    //        diff == 0 ? ANSI_COLOR_GREEN : ANSI_COLOR_RED,
    //        diff == 0 ? "BAŞARILI" : "BAŞARISIZ",
    //        ANSI_COLOR_RESET);

    // Test 2: Siyah-beyaz dama tahtası
    createTestImage(input, 3);
    memset(output, 0, sizeof(output));
    applyFilterToImageFull(input, output, FILTER_GRAYSCALE);

    grayscale_success = output[0] != input[0] ? 1 : 0;
    // // Çıktıda gri tonları olmalı
    // printf("  Test 2 (Dama Tahtası): %s%s%s\n",
    //        output[0] != input[0] ? ANSI_COLOR_GREEN : ANSI_COLOR_RED,
    //        output[0] != input[0] ? "BAŞARILI" : "BAŞARISIZ",
    //        ANSI_COLOR_RESET);
}

// Laplacian filtre testi
static void testLaplacianFilter(void) {
    uint16_t input[TEST_WIDTH * TEST_HEIGHT];
    uint16_t output[TEST_WIDTH * TEST_HEIGHT];

    // printf("Test: Laplacian Filtresi\n");

    // Test 1: Düz gri görüntü
    createTestImage(input, 0);
    memset(output, 0, sizeof(output));
    applyFilterToImageFull(input, output, FILTER_LAPLACIAN);

    // Düz görüntüde kenar olmamalı
    int edges = 0;
    for (int i = 0; i < TEST_WIDTH * TEST_HEIGHT; i++) {
        if (output[i] > 0x1000) edges++; // Belirgin kenar eşiği
    }

    // printf("  Test 1 (Düz Gri): %s%s%s\n",
    //        edges < TEST_WIDTH ? ANSI_COLOR_GREEN : ANSI_COLOR_RED,
    //        edges < TEST_WIDTH ? "BAŞARILI" : "BAŞARISIZ",
    //        ANSI_COLOR_RESET);

    // Test 2: Dikey çizgiler
    createTestImage(input, 1);
    memset(output, 0, sizeof(output));
    applyFilterToImageFull(input, output, FILTER_LAPLACIAN);

    // Dikey kenarlarda yüksek değerler olmalı
    edges = 0;
    for (int i = 0; i < TEST_WIDTH * TEST_HEIGHT; i++) {
        if (output[i] > 0x1000) edges++;
    }

    laplacian_success = edges > TEST_WIDTH ? 1 : 0;
    // printf("  Test 2 (Dikey Çizgiler): %s%s%s\n",
    //        edges > TEST_WIDTH ? ANSI_COLOR_GREEN : ANSI_COLOR_RED,
    //        edges > TEST_WIDTH ? "BAŞARILI" : "BAŞARISIZ",
    //        ANSI_COLOR_RESET);
}

// ROI optimizasyon testi
static void testROIOptimization(void) {
    uint16_t input[TEST_WIDTH * TEST_HEIGHT];
    uint16_t output1[TEST_WIDTH * TEST_HEIGHT];
    uint16_t output2[TEST_WIDTH * TEST_HEIGHT];

    // printf("Test: ROI Optimizasyonu\n");

    // Test görüntüsü oluştur
    createTestImage(input, 3);

    // ROI optimizasyonu kapalıyken işle
    setROIOptimizationEnabled(false);
    applyFilterToImageFull(input, output1, FILTER_LAPLACIAN);

    // ROI optimizasyonu açıkken işle
    setROIOptimizationEnabled(true);
    applyFilterToImageFull(input, output2, FILTER_LAPLACIAN);

    // Sonuçlar benzer olmalı (küçük farklılıklar olabilir)
    int diff = compareImages(output1, output2, TEST_WIDTH * TEST_HEIGHT);
    float diff_percent = (float)diff / (TEST_WIDTH * TEST_HEIGHT) * 100;

    roiopt_success = diff_percent < 10.0f ? 1 : 0;
    // printf("  Test (Optimizasyon Karşılaştırma): %s%s%s\n",
    //        diff_percent < 10.0f ? ANSI_COLOR_GREEN : ANSI_COLOR_RED,
    //        diff_percent < 10.0f ? "BAŞARILI" : "BAŞARISIZ",
    //        ANSI_COLOR_RESET);
    // printf("  Farklılık: %.2f%%\n", diff_percent);
}

// Merkez ROI alarm testi
static void testCenterROIAlarm(void) {
    uint16_t input1[TEST_WIDTH * TEST_HEIGHT];
    uint16_t input2[TEST_WIDTH * TEST_HEIGHT];
    uint16_t output[TEST_WIDTH * TEST_HEIGHT];

    // printf("Test: Merkez ROI Alarm\n");

    // İlk kare: Düz gri
    createTestImage(input1, 0);
    memset(output, 0, sizeof(output));
    applyFilterToImageFull(input1, output, FILTER_ROI_CENTER_ALARM);

    // İkinci kare: Dama tahtası (değişim yaratmak için)
    createTestImage(input2, 3);
    applyFilterToImageFull(input2, output, FILTER_ROI_CENTER_ALARM);

    // Merkez bölgede alarm rengi olmalı
    int alarm_pixels = 0;
    int center_y = TEST_HEIGHT / 2;
    int center_x = TEST_WIDTH / 2;

    for (int y = center_y - CENTER_ROI_SIZE/2; y < center_y + CENTER_ROI_SIZE/2; y++) {
        for (int x = center_x - CENTER_ROI_SIZE/2; x < center_x + CENTER_ROI_SIZE/2; x++) {
            if (y >= 0 && y < TEST_HEIGHT && x >= 0 && x < TEST_WIDTH) {
                if (output[y * TEST_WIDTH + x] == ALARM_COLOR) alarm_pixels++;
            }
        }
    }

    roialarm_success = alarm_pixels > 0 ? 1 : 0;
    // printf("  Test (Alarm Tetikleme): %s%s%s\n",
    //        alarm_pixels > 0 ? ANSI_COLOR_GREEN : ANSI_COLOR_RED,
    //        alarm_pixels > 0 ? "BAŞARILI" : "BAŞARISIZ",
    //        ANSI_COLOR_RESET);
}

/* USER CODE END 4 */

void StartCameraTask(void *argument)
{
  /* USER CODE BEGIN 5 */
  /* Infinite loop */
  for(;;)
  {
    osSemaphoreAcquire(sem_frame_capturedHandle, osWaitForever);
    osThreadFlagsSet(FilterTaskHandle, 0x01);
	  osDelay(10); // kamera hızı kadar beklenebilir
  }
  /* USER CODE END 5 */
}

void StartDisplayTask(void *argument)
{
  /* USER CODE BEGIN StartDisplayTask */
  /* Infinite loop */
  for(;;)
  {
	osSemaphoreAcquire(sem_filter_doneHandle, osWaitForever);
	LCD_Ioctl(E_LCD_IOCTL_DRAW_IMAGE, filtered_image);
  }
  /* USER CODE END StartDisplayTask */
}

void StartFilterTask(void *argument)
{
  /* USER CODE BEGIN StartFilterTask */
  /* Infinite loop */
  for(;;)
  {
	osThreadFlagsWait(0x01, osFlagsWaitAny, osWaitForever);
	applyFilterToImageFull(raw_image, filtered_image, filterType);
	osSemaphoreRelease(sem_filter_doneHandle);
  }
  /* USER CODE END StartFilterTask */
}

void Error_Handler(void)
{
  /* USER CODE BEGIN Error_Handler_Debug */
	HAL_GPIO_WritePin(LED3_GPIO_Port, LED3_Pin, GPIO_PIN_SET);
  /* User can add his own implementation to report the HAL error return state */
  __disable_irq();
  while (1)
  {
  }
  /* USER CODE END Error_Handler_Debug */
}
